AUTOSAR XML (schema 4-3-0)
package /test
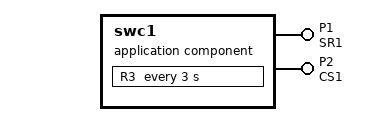
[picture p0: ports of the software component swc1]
  application sw component type swc1
    provide port P1: provided-com-specs=[SR1_DE1, SR1_DE2, SR1_DE3], provided-interface=SR1
    provide port P2: server-com-spec=OP1, required-interface=CS1
    behavior swc1_InternalBehavior
      events:
        init event E1: start-on-event=R1
        data received event E2: start-on-event=R2, data=R1.SR1_DE2
        timing event E3: start-on-event=R3, period=3
        operation invoked event E4: start-on-event=R4, operation=P2.OP1
      5 x runnable:
        R1: can-be-invoked-concurrently=true, minimum-start-interval=0.2
          data-send-points:
            access DA3: accessed-variable=P1.SR1_DE2
          data-write-access:
            access DA1: accessed-variable=P1.SR1_DE1
          data-receive-point-by-values:
            access DA4: accessed-variable=R1.SR1_DE2
            access DA: accessed-variable=R1.SR1_DE2
            access DEE: accessed-variable=R1.SR1_DE2
          data-read-access:
            access DA2: accessed-variable=R1.SR1_DE1
          sync call DA5: operation=R2.OP1, timeout=0
          sync call DA6: operation=R2.OP1, timeout=0
        R2
        R3: can-be-invoked-concurrently=true, minimum-start-interval=3
        R4: minimum-start-interval=1
        R5
  swc implementation swc1_Implementation: behavior=swc1_InternalBehavior
